# AT32F403A register map
Vendor: Keil; Series: AT32F403A; File version: 1.0
CPU: CM4 r0p1, little endian, no MPU, FPU, 4 interrupt priority bits
Registers are 32-bit, read-write, reset 0x0 unless marked. A register's access mark holds for its fields unless they carry their own. Offsets are from the block's base; [hi:lo] are bit positions; {n}, {i} and the like mark numbered series; 'fields as' and 'values as' point back to an identical list.

## DAC — Digital to analog converter
Base 0x40007400
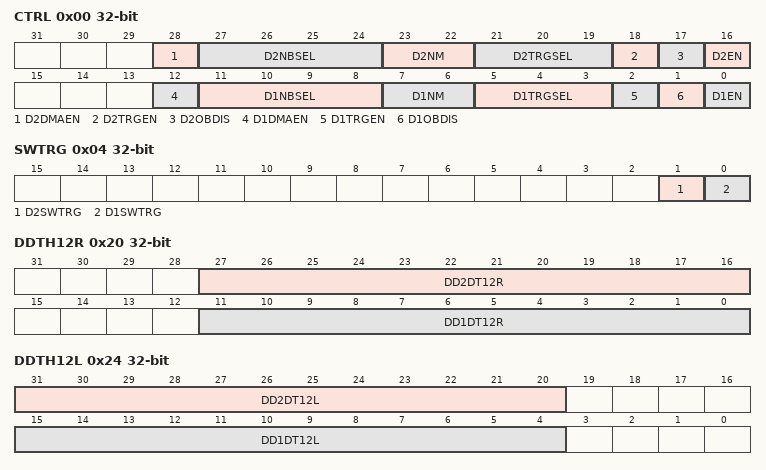
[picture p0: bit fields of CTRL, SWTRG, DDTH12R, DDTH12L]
0x00 CTRL — Control register (DAC_CTRL)
  [28] D2DMAEN — DAC2 DMA enable
  [27:24] D2NBSEL — DAC2 mask/amplitude selector
  [23:22] D2NM — DAC2 noise/triangle wave generation enable
  [21:19] D2TRGSEL — DAC2 trigger selection
  [18] D2TRGEN — DAC2 trigger enable
  [17] D2OBDIS — DAC2 output buffer disable
  [16] D2EN — DAC2 enable
  [12] D1DMAEN — DAC1 DMA enable
  [11:8] D1NBSEL — DAC1 mask/amplitude selector
  [7:6] D1NM — DAC1 noise/triangle wave generation enable
  [5:3] D1TRGSEL — DAC1 trigger selection
  [2] D1TRGEN — DAC1 trigger enable
  [1] D1OBDIS — DAC1 output buffer disable
  [0] D1EN — DAC1 enable
0x04 SWTRG wo — DAC software trigger register(DAC_SWTRIGR)
  [1] D2SWTRG — DAC2 software trigger
  [0] D1SWTRG — DAC1 software trigger
0x08 D1DTH12R — DAC1 12-bit right-aligned data holding register(DAC_D1DTH12R)
  [11:0] D1DT12R — DAC1 12-bit right-aligned data
0x0C D1DTH12L — DAC1 12-bit left aligned data holding register (DAC_D1DTH12L)
  [15:4] D1DT12L — DAC1 12-bit left-aligned data
0x10 D1DTH8R — DAC1 8-bit right aligned data holding register (DAC_D1DTH8R)
  [7:0] D1DT8R — DAC1 8-bit right-aligned data
0x14 D2DTH12R — DAC2 12-bit right aligned data holding register (DAC_D2DTH12R)
  [11:0] D2DT12R — DAC2 12-bit right-aligned data
0x18 D2DTH12L — DAC2 12-bit left aligned data holding register (DAC_D2DTH12L)
  [15:4] D2DT12L — DAC2 12-bit left-aligned data
0x1C D2DTH8R — DAC2 8-bit right-aligned data holding register (DAC_D2DTH8R)
  [7:0] D2DT8R — DAC2 8-bit right-aligned data
0x20 DDTH12R — Dual DAC 12-bit right-aligned data holding register (DAC_DDTH12R), Bits 31:28 Reserved, Bits 15:12 Reserved
  [27:16] DD2DT12R — DAC2 12-bit right-aligned data
  [11:0] DD1DT12R — DAC1 12-bit right-aligned data
0x24 DDTH12L — DUAL DAC 12-bit left aligned data holding register (DAC_DDTH12L), Bits 19:16 Reserved, Bits 3:0 Reserved
  [31:20] DD2DT12L — DAC2 12-bit right-aligned data
  [15:4] DD1DT12L — DAC1 12-bit left-aligned data
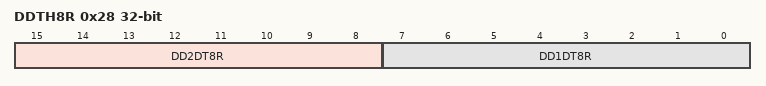
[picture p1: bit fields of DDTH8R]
0x28 DDTH8R — DUAL DAC 8-bit right aligned data holding register (DAC_DDTH8R), Bits 31:16 Reserved
  [15:8] DD2DT8R — DAC2 8-bit right-aligned data
  [7:0] DD1DT8R — DAC1 8-bit right-aligned data
0x2C D1ODT ro — DAC1 data output register (DAC_D1ODT)
  [11:0] D1ODT — DAC1 data output
0x30 D2ODT ro — DAC2 data output register (DAC_D2ODT)
  [11:0] D2ODT — DAC2 data output

## DEBUG — Debug support
Base 0xE0042000
0x00 IDCODE ro — DEBUG_IDCODE
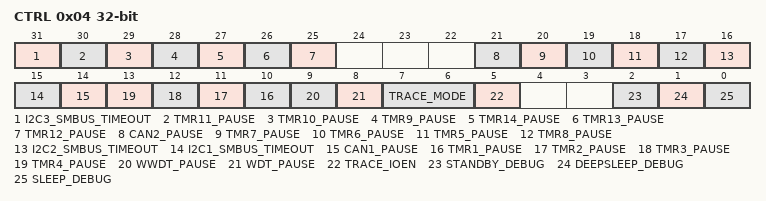
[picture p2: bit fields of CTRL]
0x04 CTRL — DEBUG_CTRL
  [31] I2C3_SMBUS_TIMEOUT
  [30] TMR11_PAUSE — Timer pause control bit
    0=Continue (The counter clock of TMRx is fed even if the core is halted); 1=Pause (The counter clock of TMRx is stopped when the core is halted)
  [29] TMR10_PAUSE — Timer pause control bit
    values as TMR11_PAUSE
  [28] TMR9_PAUSE — Timer pause control bit
    values as TMR11_PAUSE
  [27] TMR14_PAUSE — Timer pause control bit
    values as TMR11_PAUSE
  [26] TMR13_PAUSE — Timer pause control bit
    values as TMR11_PAUSE
  [25] TMR12_PAUSE — Timer pause control bit
    values as TMR11_PAUSE
  [21] CAN2_PAUSE
  [20] TMR7_PAUSE — Timer pause control bit
    values as TMR11_PAUSE
  [19] TMR6_PAUSE — Timer pause control bit
    values as TMR11_PAUSE
  [18] TMR5_PAUSE — Timer pause control bit
    values as TMR11_PAUSE
  [17] TMR8_PAUSE — Timer pause control bit
    values as TMR11_PAUSE
  [16] I2C2_SMBUS_TIMEOUT
  [15] I2C1_SMBUS_TIMEOUT
  [14] CAN1_PAUSE
  [n+9] TMR{n}_PAUSE (n=1..4) — Timer pause control bit
    values as TMR11_PAUSE
  [9] WWDT_PAUSE
    values as TMR11_PAUSE
  [8] WDT_PAUSE
    values as TMR11_PAUSE
  [7:6] TRACE_MODE
  [5] TRACE_IOEN
  [2] STANDBY_DEBUG — Debug Standby mode control bit
    on read: 0=Disabled (The whole 1.2V digital circuit is unpowered in Standby mode); 1=Enabled (The whole 1.2V digital circuit is not unpowered in Standby mode, and the system clock is provided by the internal RC oscillator (HICK)) | on write: 0=Disable (The whole 1.2V digital circuit is unpowered in Standby mode); 1=Enable (The whole 1.2V digital circuit is not unpowered in Standby mode, and the system clock is provided by the internal RC oscillator (HICK))
  [1] DEEPSLEEP_DEBUG — Debug Deepsleep mode control bit
    on read: 0=Disabled (In Deepsleep mode, all clocks in the 1.2V domain are disabled); 1=Enabled (In Deepsleep mode, system clock is provided by the internal RC oscillator (HICK)) | on write: 0=Disable (In Deepsleep mode, all clocks in the 1.2V domain are disabled); 1=Enable (In Deepsleep mode, system clock is provided by the internal RC oscillator (HICK))
  [0] SLEEP_DEBUG — Debug Sleep mode control bit
    on read: 0=Disabled (When entering Sleep mode, CPU HCLK clock is disabled, but other clocks remain active); 1=Enabled (When entering Sleep mode, all clocks keep running) | on write: 0=Disable (When entering Sleep mode, CPU HCLK clock is disabled, but other clocks remain active); 1=Enable (When entering Sleep mode, all clocks keep running)
